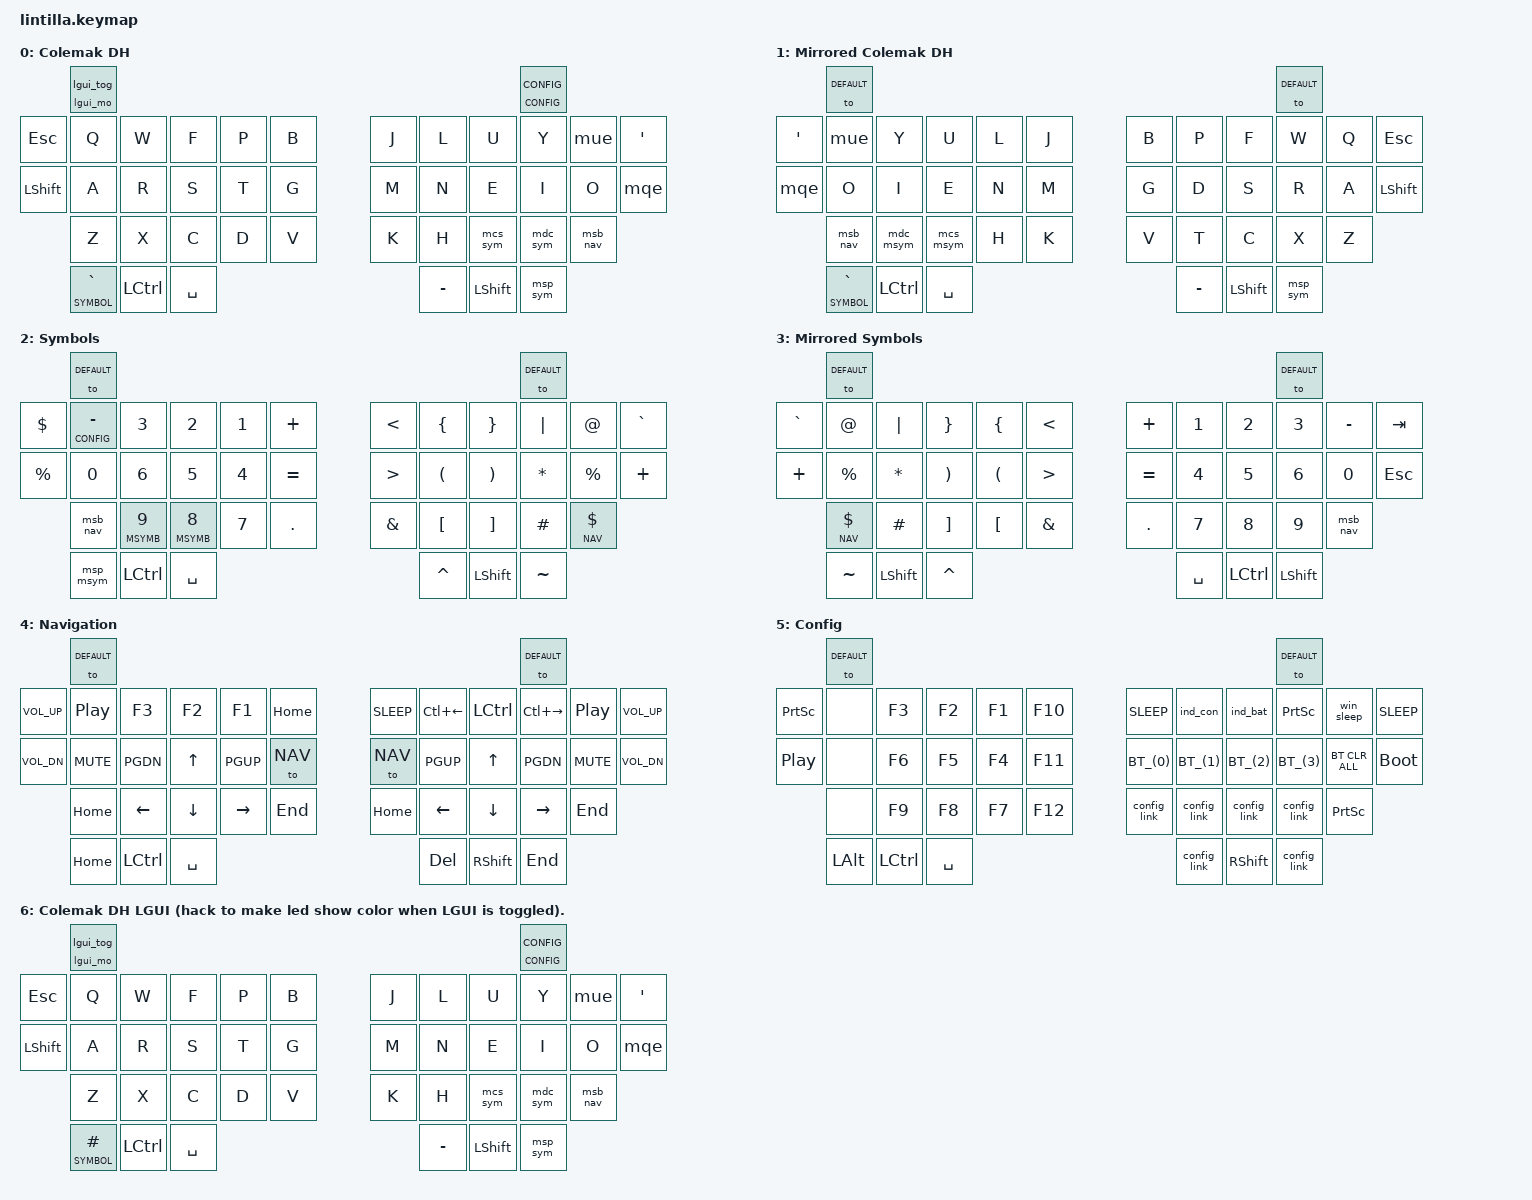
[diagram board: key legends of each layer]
#include <behaviors.dtsi>
// See https://github.com/urob/zmk-auto-layer
// #include <behaviors/num_word.dtsi>
#include <dt-bindings/zmk/bt.h>
#include <dt-bindings/zmk/keys.h>
#include <dt-bindings/zmk/outputs.h>
#include <behaviors/rgbled_widget.dtsi>

#define DEFAULT 0
#define MIRRORED 1
#define SYMBOL 2
#define MSYMB 3
#define NAV 4
#define CONFIG 5
#define LGUI_LAYER 6
// Unused Layers
/*
#define MIRROR_READY 1
#define EDITING 5
#define GAMING 6
#define AUTO_SHIFT 7
#define SHIFTED 8
*/

#define COMBO_TIMEOUT_MS 100
/* Copied (modified) from https://github.com/caksoylar/zmk-config */
#define NAMED_COMBO(NAME, BINDINGS, KEYPOS) \
  combo_##NAME { \
    timeout-ms = <COMBO_TIMEOUT_MS>; \
    bindings = <BINDINGS>; \
    key-positions = <KEYPOS>; \
    layers = <DEFAULT MIRRORED SYMBOL MSYMB NAV CONFIG LGUI_LAYER>; \
    slow-release; \
    require-prior-idle-ms = <125>; \
  };
// See https://stackoverflow.com/a/71899854 on why these multiple functions are necessary
// Can test output by putting these macros in a file test.c, then running 
// `gcc -E test.c`
#define NAMED_COMBO2(NAME, BINDINGS, KEYPOS) NAMED_COMBO(NAME, BINDINGS, KEYPOS)
// __LINE__ is the line number in the file, used here for uniqueness.
#define COMBO(BINDINGS, KEYPOS) NAMED_COMBO2(__LINE__, BINDINGS, KEYPOS)

// Magic bluetooth button
#define BT_(btnum) &bt_key btnum btnum

#define AS(keycode) &as LS(keycode) keycode

/ {
behaviors {
    /*
    as: auto_shift {
        compatible = "zmk,behavior-hold-tap";
        label = "AUTO_SHIFT";
        #binding-cells = <2>;
        tapping_term_ms = <300>;
        quick_tap_ms = <0>;
        flavor = "tap-preferred";
        bindings = <&kp>, <&kp>;
    };
    */

    bt_key: magic_bluetooth_key {
        compatible = "zmk,behavior-hold-tap";
        #binding-cells = <2>;
        flavor = "tap-preferred";
        tapping-term-ms = <500>;
        bindings = <&bt_clr>, <&bt_sel>;
    };

    lht_bal: balanced_hold_tap_for_layers {
        compatible = "zmk,behavior-hold-tap";
        #binding-cells = <2>;
        flavor = "balanced";
        tapping-term-ms = <200>;
        retro-tap;
        bindings = <&mo>, <&kp>;
    };

    kht_bal: balanced_hold_tap_for_keys {
        compatible = "zmk,behavior-hold-tap";
        #binding-cells = <2>;
        flavor = "balanced";
        tapping-term-ms = <200>;
        retro-tap;
        bindings = <&kt>, <&kp>;
    };

    // This behavior should always be used with dummy parameters like:
    // &lgui_tog_mo 0 0
    lgui_tog_mo: lgui_tog_mo {
        compatible = "zmk,behavior-hold-tap";
        #binding-cells = <2>;
        bindings = <&lgui_mo>, <&lgui_tog>;
        tapping-term-ms = <200>;
        hold-while-undecided-linger;
    };

    lht_to: tap_to_enter_layer_hold_to_mo {
        compatible = "zmk,behavior-hold-tap";
        #binding-cells = <2>;
        flavor = "balanced";
        tapping-term-ms = <200>;
        retro-tap;
        bindings = <&mo>, <&to>;
    };

    lt_sl: layer_tap_sticky_layer {
        compatible = "zmk,behavior-hold-tap";
        #binding-cells = <2>;
        flavor = "balanced";
        tapping-term-ms = <200>;
        retro-tap;
        bindings = <&mo>, <&sl>;
    };

    mue: mod_under_equals {
        compatible = "zmk,behavior-mod-morph";
        #binding-cells = <0>;
        bindings = <&kp UNDER>, <&kp EQUAL>;
        mods = <(MOD_LSFT|MOD_RSFT)>;
    };

    mqe: mod_qmark_emark {
        compatible = "zmk,behavior-mod-morph";
        #binding-cells = <0>;
        bindings = <&kp QMARK>, <&kp EXCL>;
        mods = <(MOD_LSFT|MOD_RSFT)>;
    };

    mcs: mod_comma_semi {
        compatible = "zmk,behavior-mod-morph";
        #binding-cells = <0>;
        bindings = <&kp COMMA>, <&kp SEMI>;
        mods = <(MOD_LSFT|MOD_RSFT)>;
    };

    mcs_sym: mod_comma_semi_symbol {
        compatible = "zmk,behavior-mod-morph";
        #binding-cells = <0>;
        bindings = <&lht_bal SYMBOL COMMA>, <&kp SEMI>;
        mods = <(MOD_LSFT|MOD_RSFT)>;
    };

    mcs_msym: mod_comma_semi_mirrored_symbol {
        compatible = "zmk,behavior-mod-morph";
        #binding-cells = <0>;
        bindings = <&lht_bal MSYMB COMMA>, <&kp SEMI>;
        mods = <(MOD_LSFT|MOD_RSFT)>;
    };

    mdc: mod_dot_colon {
        compatible = "zmk,behavior-mod-morph";
        #binding-cells = <0>;
        bindings = <&kp DOT>, <&kp COLON>;
        mods = <(MOD_LSFT|MOD_RSFT)>;
    };

    mdc_sym: mod_dot_colon_symbol {
        compatible = "zmk,behavior-mod-morph";
        #binding-cells = <0>;
        bindings = <&lht_bal SYMBOL DOT>, <&kp COLON>;
        mods = <(MOD_LSFT|MOD_RSFT)>;
    };

    mdc_msym: mod_dot_colon_mirrored_symbol {
        compatible = "zmk,behavior-mod-morph";
        #binding-cells = <0>;
        bindings = <&lht_bal MSYMB DOT>, <&kp COLON>;
        mods = <(MOD_LSFT|MOD_RSFT)>;
    };

    msp_sym: mod_star_plus_symbol {
        compatible = "zmk,behavior-mod-morph";
        #binding-cells = <0>;
        bindings = <&lht_bal SYMBOL STAR>, <&kp PLUS>;
        mods = <(MOD_LSFT|MOD_RSFT)>;
    };

    msp_msym: mod_star_plus_mirrored_symbol {
        compatible = "zmk,behavior-mod-morph";
        #binding-cells = <0>;
        bindings = <&lht_bal MSYMB STAR>, <&kp PLUS>;
        mods = <(MOD_LSFT|MOD_RSFT)>;
    };

    msb: mod_slash_back {
        compatible = "zmk,behavior-mod-morph";
        #binding-cells = <0>;
        bindings = <&kp SLASH>, <&kp BACKSLASH>;
        mods = <(MOD_LSFT|MOD_RSFT)>;
    };

    msb_nav: mod_slash_back_nav {
        compatible = "zmk,behavior-mod-morph";
        #binding-cells = <0>;
        bindings = <&lht_bal NAV SLASH>, <&kp BACKSLASH>;
        mods = <(MOD_LSFT|MOD_RSFT)>;
    };

    cmt: custom_mod_tap {
        compatible = "zmk,behavior-hold-tap";
        #binding-cells = <2>;
        flavor = "balanced";
        tapping-term-ms = <200>;
        bindings = <&kp>, <&kp>;
    };

    /*
    num_word: num_word {
        compatible = "zmk,behavior-auto-layer";
        #binding-cells = <1>;
        continue-list = <N0 N1 N2 N3 N4 N5 N6 N7 N8 N9 BSPC DEL DOT COMMA PLUS MINUS STAR SLASH EQUAL>;
        ignore-modifiers;
    };

    nav_word: nav_word {
      compatible = "zmk,behavior-auto-layer";
      #binding-cells = <1>;
      continue-list = <LEFT DOWN UP RIGHT PG_DN PG_UP HOME END>;
      ignore-modifiers;
    };
    */
};

macros {
    // Attempting to do
    // https://www.reddit.com/r/olkb/comments/1f6x99q/tap_into_a_layer_from_another_layer_and_exit_by/
    ltto_sym: to_symbol_layer_while_another_layer_held {
        compatible = "zmk,behavior-macro";
        #binding-cells = <0>;
        bindings =
            <&macro_press &to SYMBOL>,
            <&macro_release &to DEFAULT>;
    };

    bt_clr: bluetooth_clear {
        compatible = "zmk,behavior-macro-one-param";
        #binding-cells = <1>;
        bindings = <&macro_param_1to1 &bt_sel MACRO_PLACEHOLDER>, <&bt BT_CLR>;
    };

    bt_sel: bluetooth_select {
        compatible = "zmk,behavior-macro-one-param";
        #binding-cells = <1>;
        bindings = <&out OUT_BLE>, <&macro_param_1to2 &bt BT_SEL MACRO_PLACEHOLDER>;
    };

    flash: dongle_bootloader {
        compatible = "zmk,behavior-macro-one-param";
        #binding-cells = <1>;
        bindings = <&macro_param_1to1 &to MACRO_PLACEHOLDER>, <&bootloader>;
    };

    // Windows sleep key
    win_sleep: win_sleep {
        wait-ms = <500>;
        tap-ms = <5>;
        compatible = "zmk,behavior-macro";
        label = "WIN_SLEEP_KEY";
        #binding-cells = <0>;
        bindings = <&kp LG(X) &kp U &kp S>;
    };

    config_link: config_link {
        wait-ms = <30>;
        tap-ms = <5>;
        compatible = "zmk,behavior-macro";
        label = "CONFIG_LINK";
        #binding-cells = <0>;
        bindings = <&kp G &kp I &kp T &kp H &kp U &kp B &kp DOT &kp C &kp O &kp M &kp SLASH>
                 , <&kp K &kp O &kp V &kp A &kp S &kp A &kp P &kp SLASH>
                 , <&kp Z &kp M &kp K &kp MINUS &kp C &kp O &kp N &kp F &kp I &kp G>
                 , <&kp HASH &kp L &kp I &kp N &kp T &kp I &kp L &kp L &kp A>;
    };

    lgui_tog: toggle_lgui_layer {
        compatible = "zmk,behavior-macro";
        #binding-cells = <0>;
        bindings = <&tog LGUI_LAYER &kt LGUI>;
    };

    lgui_mo: momentary_lgui_layer {
        compatible = "zmk,behavior-macro";
        #binding-cells = <0>;
        bindings = <&macro_press &kp LGUI &mo LGUI_LAYER>
                 , <&macro_pause_for_release>
                 , <&macro_release &kp LGUI &mo LGUI_LAYER>;
    };
};

combos {
    compatible = "zmk,combos";
    //                                             KEY POSITIONS
    //       ┏━━━━━━━┓                                                                   ┏━━━━━━━┓
    //           0                                                                          1
    // ┏━━━━━╋━━━━━━━╋━━━━━━━┳━━━━━━━┳━━━━━━━┳━━━━━━━┓   ┏━━━━━━━┳━━━━━━━┳━━━━━━━┳━━━━━━━╋━━━━━━━╋━━━━━━━┓
    //    2      3       4       5       6       7           8       9      10      11      12      13
    // ┣━━━━━╋━━━━━━━╋━━━━━━━╋━━━━━━━╋━━━━━━━╋━━━━━━━┫   ┣━━━━━━━╋━━━━━━━╋━━━━━━━╋━━━━━━━╋━━━━━━━╋━━━━━━━┫
    //   14      15      16      17      18      19          20     21      22      23      24      25
    // ┗━━━━━╋━━━━━━━╋━━━━━━━╋━━━━━━━╋━━━━━━━╋━━━━━━━┫   ┣━━━━━━━╋━━━━━━━╋━━━━━━━╋━━━━━━━╋━━━━━━━╋━━━━━━━┛
    //          26      27      28      29      30          31      32      33      34      35
    //       ┗━━┳━━━━┻━━━━━━━┻┳━━━━━━┻━━━━━━┳┻━━━━━━━┻┓ ┏┻━━━━━━━┻━━━┳━━━┻━━━━━━━┻━┳━━━━━┻━━━━━━━┛
    //               36          37             38            39          40             41
    //          ┗━━━━━━━━━━━━━┻━━━━━━━━━━━━━┻━━━━━━━━━┛ ┗━━━━━━━━━━━━┻━━━━━━━━━━━━━┻━━━━━━━━━━━━━┛


    // GOLDEN RULE: All combos should be within a single finger's normal coverage range.  This means to trigger
    // a combo you must either press two keys with the same finger, or move another finger away from its normal
    // coverage range to help execute the combo.  I've found that this dramatically reduces false triggers.
    //
    // A side effect of this is that combos that require both hands should never be used.
    
    // Note that these macros can be very fragile - for instance, putting
    // comments after them on the same line can break them!

    COMBO(&kp GRAVE, 8 9)
    COMBO(&kp BSPC, 20 21)
    COMBO(&kp RET, 31 32)

    COMBO(&kp SPACE, 5 7)
    COMBO(&kp TAB, 6 7)
    COMBO(&kp LS(TAB), 6 19)
    COMBO(&kp BSPC, 18 19)
    COMBO(&kp DEL, 18 30)
    COMBO(&kp RET, 29 30)

    // Various convienience keys that are nice to have on the left hand when using the mouse with the right
    // Should be awkward enough to press that they never accidentally get hit

    COMBO(&lht_to MIRRORED MIRRORED, 2 14)
    COMBO(&kp LALT, 2 3)
    COMBO(&lht_to MSYMB MSYMB, 0 4)

    // Experimental same finger combos, left hand

    COMBO(&kp HASH, 7 19)
    COMBO(&kp SEMI, 19 30)

    // Experimental same finger combos, right hand

    COMBO(&kp LT, 8 20)
    COMBO(&kp GT, 20 31)

    COMBO(&kp LPAR, 9 21)
    COMBO(&kp LBKT, 21 32)

    COMBO(&kp RPAR, 10 22)
    COMBO(&kp RBKT, 22 33)

    COMBO(&kp LBRC, 11 23)
    COMBO(&kp RBRC, 23 34)

    COMBO(&kp EXCL, 12 24)
    COMBO(&kp QMARK, 24 35)

    COMBO(&kp LS(SQT), 12 13)
    COMBO(&kp SEMI, 13 25)
    COMBO(&kp COLON, 24 25)
};

keymap {
    compatible = "zmk,keymap";

    colemak_dh {
        display-name = "Colemak DH";
        bindings = <
//         ┏━━━━━━━┓                                                                           ┏━━━━━━━┓
           &lgui_tog_mo 0 0                                                                &lht_to CONFIG CONFIG
// ┏━━━━━━━╋━━━━━━━╋━━━━━━━┳━━━━━━━┳━━━━━━━┳━━━━━━━┓           ┏━━━━━━━┳━━━━━━━┳━━━━━━━┳━━━━━━━╋━━━━━━━╋━━━━━━━┓
    &kp ESC  &kp Q   &kp W   &kp F   &kp P   &kp B               &kp J   &kp L   &kp U   &kp Y   &mue   &kp SQT
// ┣━━━━━━━╋━━━━━━━╋━━━━━━━╋━━━━━━━╋━━━━━━━╋━━━━━━━┫           ┣━━━━━━━╋━━━━━━━╋━━━━━━━╋━━━━━━━╋━━━━━━━╋━━━━━━━┫
  &kp LSHFT  &kp A   &kp R   &kp S   &kp T   &kp G               &kp M   &kp N   &kp E   &kp I   &kp O   &mqe
// ┗━━━━━━━╋━━━━━━━╋━━━━━━━╋━━━━━━━╋━━━━━━━╋━━━━━━━┫           ┣━━━━━━━╋━━━━━━━╋━━━━━━━╋━━━━━━━╋━━━━━━━╋━━━━━━━┛
             &kp Z   &kp X   &kp C   &kp D   &kp V               &kp K   &kp H &mcs_sym &mdc_sym &msb_nav
//         ┗━━┳━━━━┻━━━━━━━┻┳━━━━━━┻━━━━━━┳┻━━━━━━━┻━━━━┓  ┏━━━┻━━━━━━━┻━━━┳━━━┻━━━━━━━┻━┳━━━━━┻━━━━━━━┛
          &lht_bal SYMBOL GRAVE  &kp LCTRL     &kp SPACE       &kp MINUS       &kp LSHFT     &msp_sym
//            ┗━━━━━━━━━━━━━┻━━━━━━━━━━━━━┻━━━━━━━━━━━━━┛  ┗━━━━━━━━━━━━━━━┻━━━━━━━━━━━━━┻━━━━━━━━━━━━━┛
        >;
    };

    mirrored_colemak_dh {
        display-name = "Mirrored Colemak DH";
        bindings = <
//         ┏━━━━━━━┓                                                                           ┏━━━━━━━┓
          &to DEFAULT                                                                         &to DEFAULT
// ┏━━━━━━━╋━━━━━━━╋━━━━━━━┳━━━━━━━┳━━━━━━━┳━━━━━━━┓           ┏━━━━━━━┳━━━━━━━┳━━━━━━━┳━━━━━━━╋━━━━━━━╋━━━━━━━┓
    &kp SQT  &mue    &kp Y   &kp U   &kp L   &kp J               &kp B   &kp P   &kp F   &kp W   &kp Q   &kp ESC
// ┣━━━━━━━╋━━━━━━━╋━━━━━━━╋━━━━━━━╋━━━━━━━╋━━━━━━━┫           ┣━━━━━━━╋━━━━━━━╋━━━━━━━╋━━━━━━━╋━━━━━━━╋━━━━━━━┫
    &mqe     &kp O   &kp I   &kp E   &kp N   &kp M               &kp G   &kp D   &kp S   &kp R   &kp A   &kp LSHFT
// ┗━━━━━━━╋━━━━━━━╋━━━━━━━╋━━━━━━━╋━━━━━━━╋━━━━━━━┫           ┣━━━━━━━╋━━━━━━━╋━━━━━━━╋━━━━━━━╋━━━━━━━╋━━━━━━━┛
        &msb_nav &mdc_msym &mcs_msym &kp H   &kp K               &kp V   &kp T   &kp C   &kp X   &kp Z
//         ┗━━┳━━━━┻━━━━━━━┻┳━━━━━━┻━━━━━━┳┻━━━━━━━┻━━━━┓  ┏━━━┻━━━━━━━┻━━━┳━━━┻━━━━━━━┻━┳━━━━━┻━━━━━━━┛
          &lht_bal SYMBOL GRAVE  &kp LCTRL     &kp SPACE       &kp MINUS       &kp LSHFT     &msp_sym
//            ┗━━━━━━━━━━━━━┻━━━━━━━━━━━━━┻━━━━━━━━━━━━━┛  ┗━━━━━━━━━━━━━━━┻━━━━━━━━━━━━━┻━━━━━━━━━━━━━┛
        >;
    };

    symbols {
        display-name = "Symbols";
        bindings = <
//         ┏━━━━━━━━━┓                                                                            ┏━━━━━━━━┓
            &to DEFAULT                                                                           &to DEFAULT
// ┏━━━━━━━╋━━━━━━━━━╋━━━━━━━┳━━━━━━━┳━━━━━━━┳━━━━━━━━━┓   ┏━━━━━━━━━┳━━━━━━━━━┳━━━━━━━━┳━━━━━━━━╋━━━━━━━━━╋━━━━━━━┓
    &kp DLLR &lht_bal CONFIG MINUS &kp N3  &kp N2  &kp N1  &kp PLUS      &kp LT    &kp LBRC  &kp RBRC &kp PIPE  &kp AT   &kp GRAVE
// ┣━━━━━━━╋━━━━━━━━━╋━━━━━━━╋━━━━━━━╋━━━━━━━╋━━━━━━━━━┫   ┣━━━━━━━━━╋━━━━━━━━━╋━━━━━━━━╋━━━━━━━━╋━━━━━━━━━╋━━━━━━━┫
   &kp PRCNT &kp N0 &kp N6 &kp N5 &kp N4  &kp EQUAL  &kp GT    &kp LPAR  &kp RPAR &kp STAR  &kp PRCNT &kp PLUS
// ┗━━━━━━━╋━━━━━━━━━╋━━━━━━━╋━━━━━━━╋━━━━━━━╋━━━━━━━━━┫   ┣━━━━━━━━━╋━━━━━━━━━╋━━━━━━━━╋━━━━━━━━╋━━━━━━━━━╋━━━━━━━┛
  &msb_nav &lht_bal MSYMB N9  &lht_bal MSYMB N8 &kp N7 &kp DOT   &kp AMPS  &kp LBKT  &kp RBKT &kp HASH  &lht_bal NAV DLLR 
//         ┗━━┳━━━━━━┻━━━━━━━┻┳━━━━━━┻━━━━━━┳┻━━━━━━━━━┻┓ ┏┻━━━━━━━━━┻━━━┳━━━━━┻━━━━━━━━┻━┳━━━━━━┻━━━━━━━━━┛
                 &msp_msym      &kp LCTRL     &kp SPACE      &kp CARET      &kp LSHFT        &kp TILDE
//            ┗━━━━━━━━━━━━━━━┻━━━━━━━━━━━━━┻━━━━━━━━━━━┛ ┗━━━━━━━━━━━━━━┻━━━━━━━━━━━━━━━━┻━━━━━━━━━━━━━━┛
        >;
    };

    mirrored_symbols {
        display-name = "Mirrored Symbols";
        bindings = <
//          ┏━━━━━━━━━┓                                                                           ┏━━━━━━━━┓
            &to DEFAULT                                                                          &to DEFAULT
// ┏━━━━━━━╋━━━━━━━━━╋━━━━━━━┳━━━━━━━┳━━━━━━━┳━━━━━━━━━┓    ┏━━━━━━━━━┳━━━━━━━━━┳━━━━━━━━┳━━━━━━━━╋━━━━━━━━━╋━━━━━━━┓
   &kp GRAVE &kp AT    &kp PIPE &kp RBRC &kp LBRC &kp LT     &kp PLUS  &kp N1    &kp N2   &kp N3   &kp MINUS &kp TAB 
// ┣━━━━━━━╋━━━━━━━━━╋━━━━━━━╋━━━━━━━╋━━━━━━━╋━━━━━━━━━┫    ┣━━━━━━━━━╋━━━━━━━━━╋━━━━━━━━╋━━━━━━━━╋━━━━━━━━━╋━━━━━━━┫
   &kp PLUS  &kp PRCNT &kp STAR &kp RPAR &kp LPAR &kp GT     &kp EQUAL &kp N4    &kp N5   &kp N6   &kp N0    &kp ESC 
// ┗━━━━━━━╋━━━━━━━━━╋━━━━━━━╋━━━━━━━╋━━━━━━━╋━━━━━━━━━┫    ┣━━━━━━━━━╋━━━━━━━━━╋━━━━━━━━╋━━━━━━━━╋━━━━━━━━━╋━━━━━━━┛
    &lht_bal NAV DLLR &kp HASH &kp RBKT &kp LBKT &kp AMPS    &kp DOT   &kp N7    &kp N8  &kp N9    &msb_nav  
//          ┗━━┳━━━━━━┻━━━━━━━┻┳━━━━━━┻━━━━━━┳┻━━━━━━━━━┻┓ ┏┻━━━━━━━━━┻━━━┳━━━━━┻━━━━━━━━┻━┳━━━━━━┻━━━━━━━━━┛
                  &kp TILDE      &kp LSHFT      &kp CARET      &kp SPACE      &kp LCTRL        &kp LSHFT
//             ┗━━━━━━━━━━━━━━━┻━━━━━━━━━━━━━┻━━━━━━━━━━━┛ ┗━━━━━━━━━━━━━━┻━━━━━━━━━━━━━━━━┻━━━━━━━━━━━━━━┛
        >;
    };

    nav {
        display-name = "Navigation";
        bindings = <
//         ┏━━━━━━━┓                                                                               ┏━━━━━━━┓
           &to DEFAULT                                                                              &to DEFAULT
// ┏━━━━━━━╋━━━━━━━╋━━━━━━━┳━━━━━━━┳━━━━━━━┳━━━━━━━┓           ┏━━━━━━━━━━┳━━━━━━━━┳━━━━━━━┳━━━━━━━╋━━━━━━━╋━━━━━━━┓
&kp C_VOL_UP &kp C_PP &kp F3 &kp F2 &kp F1  &kp HOME       &kp C_SLEEP &kp LC(LEFT) &kp LCTRL &kp LC(RIGHT) &kp C_PP &kp C_VOL_UP
// ┣━━━━━━━╋━━━━━━━╋━━━━━━━╋━━━━━━━╋━━━━━━━╋━━━━━━━┫           ┣━━━━━━━━━━╋━━━━━━━━╋━━━━━━━╋━━━━━━━╋━━━━━━━╋━━━━━━━┫
&kp C_VOL_DN &kp C_MUTE &kp PGDN &kp UP &kp PGUP &to NAV  &to NAV &kp PGUP &kp UP  &kp PGDN &kp C_MUTE &kp C_VOL_DN
// ┗━━━━━━━╋━━━━━━━╋━━━━━━━╋━━━━━━━╋━━━━━━━╋━━━━━━━┫           ┣━━━━━━━━━━╋━━━━━━━━╋━━━━━━━╋━━━━━━━╋━━━━━━━╋━━━━━━━┛
            &kp HOME &kp LEFT &kp DOWN &kp RIGHT &kp END        &kp HOME  &kp LEFT &kp DOWN &kp RIGHT &kp END
//         ┗━━┳━━━━┻━━━━━━━┻┳━━━━━━┻━━━━━━┳┻━━━━━━━┻━━━━┓  ┏━━━┻━━━━━━━━━━┻┳━━━━━━━┻━━━━━━━┻━┳━━━━━┻━━━━━━━┛
                  &kp HOME    &kp LCTRL      &kp SPACE       &kp DEL         &kp RSHFT     &kp END 
//            ┗━━━━━━━━━━━━━┻━━━━━━━━━━━━━┻━━━━━━━━━━━━━┛  ┗━━━━━━━━━━━━━━━┻━━━━━━━━━━━━━┻━━━━━━━━━━━━━┛
        >;
    };

    config {
        display-name = "Config";
        bindings = <
//         ┏━━━━━━━┓                                                                          ┏━━━━━━━┓
           &to DEFAULT                                                                       &to DEFAULT
// ┏━━━━━━━╋━━━━━━━╋━━━━━━━┳━━━━━━━┳━━━━━━━┳━━━━━━━┓          ┏━━━━━━━┳━━━━━━━┳━━━━━━━┳━━━━━━━╋━━━━━━━╋━━━━━━━┓
   &kp PSCRN &none  &kp F3  &kp F2  &kp F1  &kp F10        &kp C_SLEEP &ind_con &ind_bat &kp PSCRN &win_sleep &kp C_SLEEP
// ┣━━━━━━━╋━━━━━━━╋━━━━━━━╋━━━━━━━╋━━━━━━━╋━━━━━━━┫          ┣━━━━━━━╋━━━━━━━╋━━━━━━━╋━━━━━━━╋━━━━━━━╋━━━━━━━┫
   &kp C_PP  &none  &kp F6  &kp F5  &kp F4  &kp F11          BT_(0)  BT_(1)  BT_(2) BT_(3) &bt BT_CLR_ALL &bootloader
// ┗━━━━━━━╋━━━━━━━╋━━━━━━━╋━━━━━━━╋━━━━━━━╋━━━━━━━┫          ┣━━━━━━━╋━━━━━━━╋━━━━━━━╋━━━━━━━╋━━━━━━━╋━━━━━━━┛
             &none  &kp F9  &kp F8  &kp F7  &kp F12      &config_link &config_link &config_link &config_link  &kp PSCRN
//         ┗━━┳━━━━┻━━━━━━━┻┳━━━━━━┻━━━━━━┳┻━━━━━━━┻━━━━┓ ┏━━━┻━━━━━━━┻━━━┳━━━┻━━━━━━━┻━┳━━━━━┻━━━━━━━┛
                  &kp LALT    &kp LCTRL      &kp SPACE      &config_link   &kp RSHFT  &config_link
//            ┗━━━━━━━━━━━━━┻━━━━━━━━━━━━━┻━━━━━━━━━━━━━┛ ┗━━━━━━━━━━━━━━━┻━━━━━━━━━━━━━┻━━━━━━━━━━━━━┛
        >;
    };

    // This is a direct copy of the colemak_dh layer, see 
    // https://github.com/caksoylar/zmk-rgbled-widget/issues/20 for context.
    lgui {
        display-name = "Colemak DH LGUI (hack to make led show color when LGUI is toggled).";
        bindings = <
//         ┏━━━━━━━┓                                                                           ┏━━━━━━━┓
          &lgui_tog_mo 0 0                                                                  &lht_to CONFIG CONFIG
// ┏━━━━━━━╋━━━━━━━╋━━━━━━━┳━━━━━━━┳━━━━━━━┳━━━━━━━┓           ┏━━━━━━━┳━━━━━━━┳━━━━━━━┳━━━━━━━╋━━━━━━━╋━━━━━━━┓
    &kp ESC  &kp Q   &kp W   &kp F   &kp P   &kp B               &kp J   &kp L   &kp U   &kp Y   &mue   &kp SQT
// ┣━━━━━━━╋━━━━━━━╋━━━━━━━╋━━━━━━━╋━━━━━━━╋━━━━━━━┫           ┣━━━━━━━╋━━━━━━━╋━━━━━━━╋━━━━━━━╋━━━━━━━╋━━━━━━━┫
  &kp LSHFT  &kp A   &kp R   &kp S   &kp T   &kp G               &kp M   &kp N   &kp E   &kp I   &kp O   &mqe
// ┗━━━━━━━╋━━━━━━━╋━━━━━━━╋━━━━━━━╋━━━━━━━╋━━━━━━━┫           ┣━━━━━━━╋━━━━━━━╋━━━━━━━╋━━━━━━━╋━━━━━━━╋━━━━━━━┛
             &kp Z   &kp X   &kp C   &kp D   &kp V               &kp K   &kp H &mcs_sym &mdc_sym &msb_nav
//         ┗━━┳━━━━┻━━━━━━━┻┳━━━━━━┻━━━━━━┳┻━━━━━━━┻━━━━┓  ┏━━━┻━━━━━━━┻━━━┳━━━┻━━━━━━━┻━┳━━━━━┻━━━━━━━┛
         &lht_bal SYMBOL HASH   &kp LCTRL     &kp SPACE       &kp MINUS       &kp LSHFT     &msp_sym
//            ┗━━━━━━━━━━━━━┻━━━━━━━━━━━━━┻━━━━━━━━━━━━━┛  ┗━━━━━━━━━━━━━━━┻━━━━━━━━━━━━━┻━━━━━━━━━━━━━┛
        >;
    };

    // ---------------------------- Not actively used layers. --------------------------------------------

    /*
    // To awkward to have toggle keys to get to this layer and use it
    mirror_ready_colemak_dh {
        display-name = "Colemak DH Mirror Ready";
        bindings = <
//         ┏━━━━━━━┓                                                                           ┏━━━━━━━┓
        &lht_to SYMBOL SYMBOL                                                          &lht_to CONFIG CONFIG
// ┏━━━━━━━╋━━━━━━━╋━━━━━━━┳━━━━━━━┳━━━━━━━┳━━━━━━━┓           ┏━━━━━━━┳━━━━━━━┳━━━━━━━┳━━━━━━━╋━━━━━━━╋━━━━━━━┓
    &kp TAB  &kp Q   &kp W   &kp F   &kp P   &kp B               &kp J   &kp L   &kp U   &kp Y   &mue   &kp SQT
// ┣━━━━━━━╋━━━━━━━╋━━━━━━━╋━━━━━━━╋━━━━━━━╋━━━━━━━┫           ┣━━━━━━━╋━━━━━━━╋━━━━━━━╋━━━━━━━╋━━━━━━━╋━━━━━━━┫
    &kp ESC  &kp A   &kp R   &kp S   &kp T   &kp G               &kp M   &kp N   &kp E   &kp I   &kp O   &mqe
// ┗━━━━━━━╋━━━━━━━╋━━━━━━━╋━━━━━━━╋━━━━━━━╋━━━━━━━┫           ┣━━━━━━━╋━━━━━━━╋━━━━━━━╋━━━━━━━╋━━━━━━━╋━━━━━━━┛
             &kp Z   &kp X   &kp C   &kp D   &kp V               &kp K   &kp H &mcs_sym &mdc_sym &msb_nav
//         ┗━━┳━━━━┻━━━━━━━┻┳━━━━━━┻━━━━━━┳┻━━━━━━━┻━━━━┓  ┏━━━┻━━━━━━━┻━━━┳━━━┻━━━━━━━┻━┳━━━━━┻━━━━━━━┛
           &kp LGUI  &lht_to MIRRORED MIRRORED &kp SPACE       &kp MINUS       &kp LSHFT     &msp_sym
//            ┗━━━━━━━━━━━━━┻━━━━━━━━━━━━━┻━━━━━━━━━━━━━┛  ┗━━━━━━━━━━━━━━━┻━━━━━━━━━━━━━┻━━━━━━━━━━━━━┛
        >;
    };

    // This layer was cool, but I kept getting it mixed up with the symbol layer, and it is redundant.
    editing {
        display-name = "editing";
        bindings = <
//         ┏━━━━━━━┓                                                                               ┏━━━━━━━┓
           &to DEFAULT                                                                              &to DEFAULT
// ┏━━━━━━━╋━━━━━━━╋━━━━━━━┳━━━━━━━┳━━━━━━━┳━━━━━━━┓           ┏━━━━━━━━━━┳━━━━━━━━┳━━━━━━━┳━━━━━━━╋━━━━━━━╋━━━━━━━┓
    &kp TAB &kp MINUS &kp N3  &kp N2  &kp N1  &kp PLUS         &kp PGUP  &kp LC(LEFT) &kp BSPC &kp PIPE &kp DEL &kp TILDE 
// ┣━━━━━━━╋━━━━━━━╋━━━━━━━╋━━━━━━━╋━━━━━━━╋━━━━━━━┫           ┣━━━━━━━━━━╋━━━━━━━━╋━━━━━━━╋━━━━━━━╋━━━━━━━╋━━━━━━━┫
   &kp ESC &kp N0    &kp N6  &kp N5  &kp N4  &kp EQUAL        &kp SQT     &kp SEMI &kp DEL &kp STAR &kp END   &kp CARET
// ┗━━━━━━━╋━━━━━━━╋━━━━━━━╋━━━━━━━╋━━━━━━━╋━━━━━━━┫           ┣━━━━━━━━━━╋━━━━━━━━╋━━━━━━━╋━━━━━━━╋━━━━━━━╋━━━━━━━┛
           &kp SLASH &kp N9  &kp N8  &kp N7  &kp DOT           &kp LS(SQT) &kp COLON &kp DEL &kp HASH &kp LC(DEL)
//         ┗━━┳━━━━┻━━━━━━━┻┳━━━━━━┻━━━━━━┳┻━━━━━━━┻━━━━┓  ┏━━━┻━━━━━━━━━━┻┳━━━━━━━┻━━━━━━━┻━┳━━━━━┻━━━━━━━┛
              &kp RET        &kp LCTRL     &kp SPACE            &kp PGUP       &kp LS(SQT)       &kp SQT
//            ┗━━━━━━━━━━━━━┻━━━━━━━━━━━━━┻━━━━━━━━━━━━━┛  ┗━━━━━━━━━━━━━━━┻━━━━━━━━━━━━━┻━━━━━━━━━━━━━┛
        >;
    };

    gaming {
        display-name = "Gaming";
        bindings = <
//         ┏━━━━━━━┓                                                                           ┏━━━━━━━┓
           &to DEFAULT                                                                         &to DEFAULT
// ┏━━━━━━━╋━━━━━━━╋━━━━━━━┳━━━━━━━┳━━━━━━━┳━━━━━━━┓           ┏━━━━━━━┳━━━━━━━┳━━━━━━━┳━━━━━━━╋━━━━━━━╋━━━━━━━┓
    &kp TAB  &kp LALT &kp N0 &kp UP &kp N1  &kp N2               &kp J   &kp L   &kp U   &kp Y  &kp UNDER &kp SQT
// ┣━━━━━━━╋━━━━━━━╋━━━━━━━╋━━━━━━━╋━━━━━━━╋━━━━━━━┫           ┣━━━━━━━╋━━━━━━━╋━━━━━━━╋━━━━━━━╋━━━━━━━╋━━━━━━━┫
    &kp ESC  &kp LSHFT &kp LEFT  &kp DOWN  &kp RIGHT            &kp N3  &kp M   &kp N   &kp E   &kp I  &kp O   &kp MINUS
// ┗━━━━━━━╋━━━━━━━╋━━━━━━━╋━━━━━━━╋━━━━━━━╋━━━━━━━┫           ┣━━━━━━━╋━━━━━━━╋━━━━━━━╋━━━━━━━╋━━━━━━━╋━━━━━━━┛
        &kp LCTRL   &kp N7   &kp N6   &kp N5   &kp N4              &kp K   &kp H   &mcs    &mdc   &msb_nav
//         ┗━━┳━━━━┻━━━━━━━┻┳━━━━━━┻━━━━━━┳┻━━━━━━━┻━━━━┓  ┏━━━┻━━━━━━━┻━━━┳━━━┻━━━━━━━┻━┳━━━━━┻━━━━━━━┛
                 &kp LGUI     &kp RET      &kp SPACE          &kp BSPC       &mt LSHFT ESC    &lt NAV DEL
//            ┗━━━━━━━━━━━━━┻━━━━━━━━━━━━━┻━━━━━━━━━━━━━┛  ┗━━━━━━━━━━━━━━━┻━━━━━━━━━━━━━┻━━━━━━━━━━━━━┛
        >;
    };

    colemak_dh_autoshift {
        display-name = "Colemak DH Autoshift";
        bindings = <
//         ┏━━━━━━━┓                                                                           ┏━━━━━━━┓
         &num_word SYMBOL                                                               &nav_word NAV
// ┏━━━━━━━╋━━━━━━━╋━━━━━━━┳━━━━━━━┳━━━━━━━┳━━━━━━━┓           ┏━━━━━━━┳━━━━━━━┳━━━━━━━┳━━━━━━━╋━━━━━━━╋━━━━━━━┓
    &kp TAB  AS(Q)   AS(W)   AS(F)   AS(P)   AS(B)               AS(J)   AS(L)   AS(U)   AS(Y)  &caps_word AS(SQT)
// ┣━━━━━━━╋━━━━━━━╋━━━━━━━╋━━━━━━━╋━━━━━━━╋━━━━━━━┫           ┣━━━━━━━╋━━━━━━━╋━━━━━━━╋━━━━━━━╋━━━━━━━╋━━━━━━━┫
    &kp ESC  AS(A)   AS(R)   AS(S)   AS(T)   AS(G)               AS(M)   AS(N)   AS(E)   AS(I)  AS(O)   AS(MINUS)
// ┗━━━━━━━╋━━━━━━━╋━━━━━━━╋━━━━━━━╋━━━━━━━╋━━━━━━━┫           ┣━━━━━━━╋━━━━━━━╋━━━━━━━╋━━━━━━━╋━━━━━━━╋━━━━━━━┛
             AS(Z)   AS(X)   AS(C)   AS(D)   AS(V)               AS(K)   AS(H)   &as SEMI COMMA    &as COLON DOT   &as BACKSLASH SLASH
//         ┗━━┳━━━━┻━━━━━━━┻┳━━━━━━┻━━━━━━┳┻━━━━━━━┻━━━━┓  ┏━━━┻━━━━━━━┻━━━┳━━━┻━━━━━━━┻━┳━━━━━┻━━━━━━━┛
               &kp LGUI    &mt LCTRL RET   &kp SPACE       &kp BSPC     &lt SYMBOL ESC  &lt NAV DEL
//            ┗━━━━━━━━━━━━━┻━━━━━━━━━━━━━┻━━━━━━━━━━━━━┛  ┗━━━━━━━━━━━━━━━┻━━━━━━━━━━━━━┻━━━━━━━━━━━━━┛
        >;
    };

    // TODO try &ltto on the shifted key if i can find some keys to change layers further on the shifted layer
    colemak_dh_shifted {
        display-name = "Colemak DH Shifted";
        bindings = <
//                ┏━━━━━━━┓                                                                                                                           ┏━━━━━━━┓
            &num_word SYMBOL                                                                                                                   &nav_word NAV
// ┏━━━━━━━━━━━╋━━━━━━━━━━━━━━━╋━━━━━━━━━━━━┳━━━━━━━━━━━━┳━━━━━━━━━━━━┳━━━━━━━━━━━━━━┓  ┏━━━━━━━━━━━━━━┳━━━━━━━━━━━━━━━┳━━━━━━━━━━━━━━┳━━━━━━━━━━━━━━╋━━━━━━━━━━━━╋━━━━━━━━━━━━━━┓
    &kp LS(TAB) &as MINUS LS(Q) &as N3 LS(W) &as N2 LS(F) &as N1 LS(P) &as PLUS LS(B)    &as LT LS(J) &as LBRC LS(L) &as RBRC LS(U) &as PIPE LS(Y) &as AT TILDE  &as GRAVE LS(SQT)
// ┣━━━━━━━━━━━╋━━━━━━━━━━━━━━━╋━━━━━━━━━━━━╋━━━━━━━━━━━━╋━━━━━━━━━━━━╋━━━━━━━━━━━━━━┫  ┣━━━━━━━━━━━━━━╋━━━━━━━━━━━━━━━╋━━━━━━━━━━━━━━╋━━━━━━━━━━━━━━╋━━━━━━━━━━━━╋━━━━━━━━━━━━━━┫
     &kp ESC     &as N0 LS(A)    &as N6 LS(R) &as N5 LS(S) &as N4 LS(T) &as EQUAL LS(G)   &as GT LS(M) &as LPAR LS(N)  &as RPAR LS(E) &as STAR LS(I) &as PRCNT LS(O) &as EXCL QMARK
// ┗━━━━━━━━━━━╋━━━━━━━━━━━━━━━╋━━━━━━━━━━━━╋━━━━━━━━━━━━╋━━━━━━━━━━━━╋━━━━━━━━━━━━━━┫  ┣━━━━━━━━━━━━━━╋━━━━━━━━━━━━━━━╋━━━━━━━━━━━━━━╋━━━━━━━━━━━━━━╋━━━━━━━━━━━━╋━━━━━━━━━━━━━━┛
                &as SLASH LS(Z) &as N9 LS(X) &as N8 LS(C) &as N7 LS(D) &as DOT LS(V)    &as AMPS LS(K) &as LBKT LS(H)  &as RBKT SEMI  &as HASH COLON &as DLLR BACKSLASH
//             ┗━━┳━━━━━━━━━━━━┻━━━━━━━━━━━━┻┳━━━━━━━━━━━┻━━━━━━━━━━━┳┻━━━━━━━━━━━━━━┻┓┏┻━━━━━━━━━━━━━━┻━━━━━━━━━━━┳━━━┻━━━━━━━━━━━━━━┻━┳━━━━━━━━━━━━┻━━━━━━━━━━━━┛
                       &kp LGUI                  &kp LCTRL               &kp SPACE          &kp DEL                         &none                 &kp LS(RET)
//                ┗━━━━━━━━━━━━━━━━━━━━━━━━━━┻━━━━━━━━━━━━━━━━━━━━━━━┻━━━━━━━━━━━━━━━━┛┗━━━━━━━━━━━━━━━━━━━━━━━━━━━┻━━━━━━━━━━━━━━━━━━━━┻━━━━━━━━━━━━━━━━━━━━━┛
        >;
    };
    */
};
};

// vim: expandtab softtabstop=4 shiftwidth=4 filetype=dts
